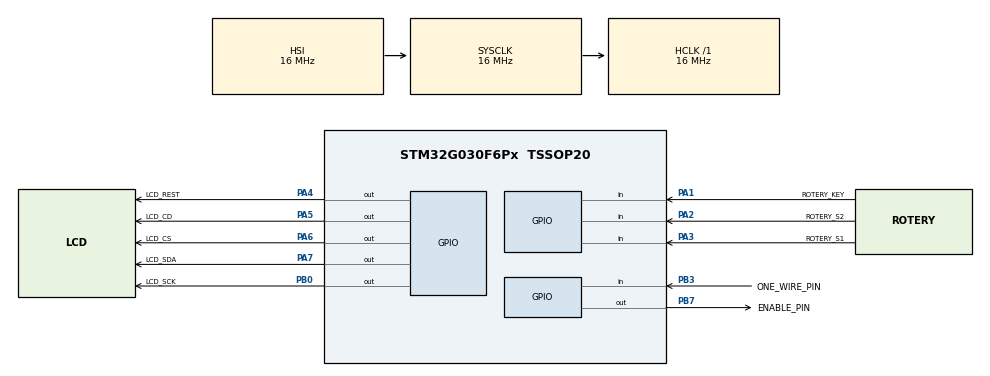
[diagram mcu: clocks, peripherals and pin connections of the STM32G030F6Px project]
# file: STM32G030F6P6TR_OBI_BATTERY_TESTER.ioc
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Mcu.Family=STM32G0
Mcu.Name=STM32G030F6Px
Mcu.Package=TSSOP20
PA1.GPIO_Label=ROTERY_KEY
PA1.GPIO_PuPd=GPIO_PULLUP
PA1.Signal=GPIO_Input
PA14-BOOT0__PA15.StandardMode=true
PA2.GPIO_Label=ROTERY_S2
PA2.GPIO_PuPd=GPIO_PULLUP
PA2.Signal=GPIO_Input
PA3.GPIO_Label=ROTERY_S1
PA3.GPIO_PuPd=GPIO_PULLUP
PA3.Signal=GPIO_Input
PA4.GPIO_Label=LCD_REST
PA4.Signal=GPIO_Output
PA5.GPIO_Label=LCD_CD
PA5.Signal=GPIO_Output
PA6.GPIO_Label=LCD_CS
PA6.Signal=GPIO_Output
PA7.GPIO_Label=LCD_SDA
PA7.Signal=GPIO_Output
PB0.GPIO_Label=LCD_SCK
PB0.Signal=GPIO_Output
PB0__PB1__PB2__PA8.StandardMode=true
PB3.GPIO_Label=ONE_WIRE_PIN
PB3.Signal=GPIO_Input
PB3__PB4__PB5__PB6.StandardMode=true
PB7.GPIO_Label=ENABLE_PIN
PB7.Signal=GPIO_Output
PB7__PB8.StandardMode=true
PC14-OSC32_IN\ (PC14)__PB9.StandardMode=true
ProjectManager.HeapSize=0x200
ProjectManager.StackSize=0x400
ProjectManager.TargetToolchain=CMake
RCC.AHBFreq_Value=16000000
RCC.CortexFreq_Value=16000000
RCC.EXTERNAL_CLOCK_VALUE=12288000
RCC.HCLKFreq_Value=16000000
RCC.HSE_VALUE=8000000
RCC.HSI_VALUE=16000000
RCC.LSE_VALUE=32768
RCC.SYSCLKFreq_VALUE=16000000
RCC.VCOOutputFreq_Value=128000000
board=custom

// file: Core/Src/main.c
/* USER CODE BEGIN Header */
/**
  ******************************************************************************
  * @file           : main.c
  * @brief          : Main program body
  ******************************************************************************
  * @attention
  *
  * Copyright (c) 2026 STMicroelectronics.
  * All rights reserved.
  *
  * This software is licensed under terms that can be found in the LICENSE file
  * in the root directory of this software component.
  * If no LICENSE file comes with this software, it is provided AS-IS.
  *
  STM32GO30F6P6TR_OBI_BATTERY_TESTER
  ******************************************************************************
  */
/* USER CODE END Header */
#include "main.h"

/* USER CODE BEGIN Includes */
#include "makita_obi.h"
#include "obi_ui.h"
#include "rotary_encoder.h"
#include "st7567.h"

/* USER CODE END Includes */

void SystemClock_Config(void);
static void MX_GPIO_Init(void);

int main(void)
{

  /* MCU Configuration--------------------------------------------------------*/

  /* Reset of all peripherals, Initializes the Flash interface and the Systick. */
  HAL_Init();

  /* Configure the system clock */
  SystemClock_Config();

  /* Initialize all configured peripherals */
  MX_GPIO_Init();
  /* USER CODE BEGIN 2 */
  lcd_init();
  lcd_clear();
  makita_obi_init();
  rotary_encoder_init();
  obi_ui_init();

  /* USER CODE END 2 */

  /* Infinite loop */
  /* USER CODE BEGIN WHILE */
  while (1)
  {
    RotaryEncoderEvent encoder_event = rotary_encoder_poll();

    if (encoder_event.rotation != 0)
    {
      obi_ui_move(encoder_event.rotation);
    }
    else if (encoder_event.button_pressed != 0U)
    {
      obi_ui_activate();
    }
    /* USER CODE END WHILE */

  }
}

void SystemClock_Config(void)
{
  RCC_OscInitTypeDef RCC_OscInitStruct = {0};
  RCC_ClkInitTypeDef RCC_ClkInitStruct = {0};

  /** Configure the main internal regulator output voltage
  */
  HAL_PWREx_ControlVoltageScaling(PWR_REGULATOR_VOLTAGE_SCALE1);

  /** Initializes the RCC Oscillators according to the specified parameters
  * in the RCC_OscInitTypeDef structure.
  */
  RCC_OscInitStruct.OscillatorType = RCC_OSCILLATORTYPE_HSI;
  RCC_OscInitStruct.HSIState = RCC_HSI_ON;
  RCC_OscInitStruct.HSIDiv = RCC_HSI_DIV1;
  RCC_OscInitStruct.HSICalibrationValue = RCC_HSICALIBRATION_DEFAULT;
  RCC_OscInitStruct.PLL.PLLState = RCC_PLL_NONE;
  if (HAL_RCC_OscConfig(&RCC_OscInitStruct) != HAL_OK)
  {
    Error_Handler();
  }

  /** Initializes the CPU, AHB and APB buses clocks
  */
  RCC_ClkInitStruct.ClockType = RCC_CLOCKTYPE_HCLK|RCC_CLOCKTYPE_SYSCLK
                              |RCC_CLOCKTYPE_PCLK1;
  RCC_ClkInitStruct.SYSCLKSource = RCC_SYSCLKSOURCE_HSI;
  RCC_ClkInitStruct.AHBCLKDivider = RCC_SYSCLK_DIV1;
  RCC_ClkInitStruct.APB1CLKDivider = RCC_HCLK_DIV1;

  if (HAL_RCC_ClockConfig(&RCC_ClkInitStruct, FLASH_LATENCY_0) != HAL_OK)
  {
    Error_Handler();
  }
}

static void MX_GPIO_Init(void)
{
  GPIO_InitTypeDef GPIO_InitStruct = {0};

  /* GPIO Ports Clock Enable */
  __HAL_RCC_GPIOB_CLK_ENABLE();
  __HAL_RCC_GPIOA_CLK_ENABLE();

  /*Configure GPIO pin Output Level */
  HAL_GPIO_WritePin(GPIOB, ENABLE_PIN_Pin|LCD_SCK_Pin, GPIO_PIN_RESET);

  /*Configure GPIO pin Output Level */
  HAL_GPIO_WritePin(GPIOA, LCD_CD_Pin|LCD_SDA_Pin, GPIO_PIN_RESET);
  HAL_GPIO_WritePin(GPIOA, LCD_REST_Pin|LCD_CS_Pin, GPIO_PIN_SET);

  /*Configure GPIO pins : ENABLE_PIN_Pin LCD_SCK_Pin */
  GPIO_InitStruct.Pin = ENABLE_PIN_Pin|LCD_SCK_Pin;
  GPIO_InitStruct.Mode = GPIO_MODE_OUTPUT_PP;
  GPIO_InitStruct.Pull = GPIO_NOPULL;
  GPIO_InitStruct.Speed = GPIO_SPEED_FREQ_LOW;
  HAL_GPIO_Init(GPIOB, &GPIO_InitStruct);

  /*Configure GPIO pin : ONE_WIRE_PIN_Pin */
  GPIO_InitStruct.Pin = ONE_WIRE_PIN_Pin;
  GPIO_InitStruct.Mode = GPIO_MODE_INPUT;
  GPIO_InitStruct.Pull = GPIO_NOPULL;
  HAL_GPIO_Init(ONE_WIRE_PIN_GPIO_Port, &GPIO_InitStruct);

  /*Configure GPIO pins : ROTERY_KEY_Pin ROTERY_S2_Pin ROTERY_S1_Pin */
  GPIO_InitStruct.Pin = ROTERY_KEY_Pin|ROTERY_S2_Pin|ROTERY_S1_Pin;
  GPIO_InitStruct.Mode = GPIO_MODE_INPUT;
  GPIO_InitStruct.Pull = GPIO_PULLUP;
  HAL_GPIO_Init(GPIOA, &GPIO_InitStruct);

  /*Configure GPIO pins : LCD_REST_Pin LCD_CD_Pin LCD_CS_Pin LCD_SDA_Pin */
  GPIO_InitStruct.Pin = LCD_REST_Pin|LCD_CD_Pin|LCD_CS_Pin|LCD_SDA_Pin;
  GPIO_InitStruct.Mode = GPIO_MODE_OUTPUT_PP;
  GPIO_InitStruct.Pull = GPIO_NOPULL;
  GPIO_InitStruct.Speed = GPIO_SPEED_FREQ_LOW;
  HAL_GPIO_Init(GPIOA, &GPIO_InitStruct);

}

void Error_Handler(void)
{
  __disable_irq();
  while (1)
  {
  }
}
